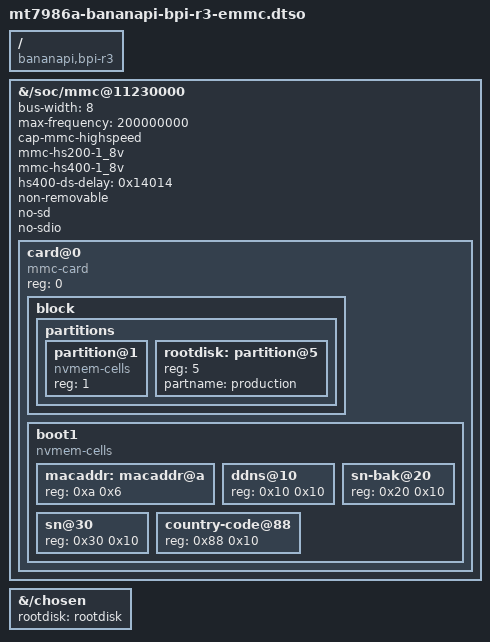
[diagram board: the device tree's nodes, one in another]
// SPDX-License-Identifier: (GPL-2.0 OR MIT)
/*
 * Copyright (C) 2021 MediaTek Inc.
 * Author: Sam.Shih <sam.shih@mediatek.com>
 */

/dts-v1/;
/plugin/;

/ {
	compatible = "bananapi,bpi-r3", "mediatek,mt7986a";

	fragment@0 {
		target-path = "/soc/mmc@11230000";
		__overlay__ {
			#address-cells = <1>;
			#size-cells = <0>;
			bus-width = <8>;
			max-frequency = <200000000>;
			cap-mmc-highspeed;
			mmc-hs200-1_8v;
			mmc-hs400-1_8v;
			hs400-ds-delay = <0x14014>;
			non-removable;
			no-sd;
			no-sdio;
			status = "okay";

			card@0 {
				compatible = "mmc-card";
				reg = <0>;

				block {
					partitions {
						#address-cells = <1>;
						#size-cells = <0>;

						partition@1 {
							reg = <1>;
							compatible = "nvmem-cells";
						};

						rootdisk: partition@5 {
							reg = <5>;
							partname = "production";
						};
					};
				};

				boot1 {
					compatible = "nvmem-cells";
					#address-cells = <1>;
					#size-cells = <1>;

					macaddr: macaddr@a {
						reg = <0xa 0x6>;
					};

					ddns@10 {
						reg = <0x10 0x10>;
					};

					sn-bak@20 {
						reg = <0x20 0x10>;
					};

					sn@30 {
						reg = <0x30 0x10>;
					};

					country-code@88 {
						reg = <0x88 0x10>;
					};
				};
			};
		};
	};

	fragment@1 {
		target-path = "/chosen";
		__overlay__ {
			rootdisk = <&rootdisk>;
		};
	};
};
